# WS53 register map
File version: 0.1.0-experimental
Registers are 32-bit, read-write, no defined reset value unless marked. A register's access mark holds for its fields unless they carry their own. Offsets are from the block's base; [hi:lo] are bit positions; {n}, {i} and the like mark numbered series.

## AUDIO_CMU
Base 0x57008600
0x00 NEW_CFG0 — CMU_NEW_CFG0 partial view; preserve all other bits
  [0] AUDIO_DIVIDER_RESET_N — CMU_DIV_AD_RSTN_SYNC_BIT: SDK sets before I2S gate, clears before disabling gate; shared audio reset ownership required

## GPIO0
Base 0x5700C000
0x00 GPIO_SW_OUT
  [22:0] GPIO_SW_OUT — GPIO data. Output: written value drives I/O; Input: reads external port
0x04 GPIO_SW_OEN
  [22:0] PINS — Direction bitmap: each 0 bit selects output, each 1 bit selects input; not a whole-register mode enum
0x08 GPIO_SW_CTL
  [22:0] GPIO_SW_CTL — Per-pin data source control; SDK supplies bit get/set helpers but does not establish selection encodings
0x0C GPIO_INT_EN
  [22:0] GPIO_INT_EN — Interrupt enable: 0=normal GPIO; 1=interrupt port
0x10 GPIO_INT_MASK
  [22:0] GPIO_INT_MASK — Interrupt mask: 0=not masked; 1=masked
0x14 GPIO_INT_TYPE
  [22:0] PINS — Trigger bitmap: each 0 bit selects level, each 1 bit selects edge
0x18 GPIO_INT_POLARITY
  [22:0] PINS — Polarity bitmap: each 0 bit selects low/falling, each 1 bit high/rising
0x1C GPIO_INT_DEDGE
  [22:0] PINS — Dual-edge bitmap: each 1 bit enables detection on both edges of that input
0x20 GPIO_INT_DEBOUNCE
  [22:0] GPIO_INT_DEBOUNCE — Debounce enable: 0=disabled; 1=enabled
0x24 GPIO_INT_RAW ro
  [22:0] GPIO_INT_RAW — Raw interrupt status (before mask): 0=no interrupt; 1=interrupt
0x28 GPIO_INTR ro
  [22:0] GPIO_INTR — Interrupt status (after mask): 0=no interrupt; 1=interrupt
0x2C GPIO_INT_EOI wo
  [22:0] GPIO_INT_EOI write-1-clears — Edge interrupt clear: 0=no clear; 1=clear interrupt
0x30 GPIO_DATA_SET wo
  [22:0] GPIO_DATA_SET write-1-sets — Write 1 to set corresponding GPIO_SW_OUT bits
0x34 GPIO_DATA_CLR wo
  [22:0] GPIO_DATA_CLR write-1-clears — Write 1 to clear corresponding GPIO_SW_OUT bits

## GPIO2
Base 0x57010000
0x00 GPIO_SW_OUT
  [2:0] GPIO_SW_OUT — GPIO data. Output: written value drives I/O; Input: reads external port
0x04 GPIO_SW_OEN
  [2:0] PINS — Direction bitmap: each 0 bit selects output, each 1 bit selects input; not a whole-register mode enum
0x08 GPIO_SW_CTL
  [2:0] GPIO_SW_CTL — Per-pin data source control; SDK supplies bit get/set helpers but does not establish selection encodings
0x0C GPIO_INT_EN
  [2:0] GPIO_INT_EN — Interrupt enable: 0=normal GPIO; 1=interrupt port
0x10 GPIO_INT_MASK
  [2:0] GPIO_INT_MASK — Interrupt mask: 0=not masked; 1=masked
0x14 GPIO_INT_TYPE
  [2:0] PINS — Trigger bitmap: each 0 bit selects level, each 1 bit selects edge
0x18 GPIO_INT_POLARITY
  [2:0] PINS — Polarity bitmap: each 0 bit selects low/falling, each 1 bit high/rising
0x1C GPIO_INT_DEDGE
  [2:0] PINS — Dual-edge bitmap: each 1 bit enables detection on both edges of that input
0x20 GPIO_INT_DEBOUNCE
  [2:0] GPIO_INT_DEBOUNCE — Debounce enable: 0=disabled; 1=enabled
0x24 GPIO_INT_RAW ro
  [2:0] GPIO_INT_RAW — Raw interrupt status (before mask): 0=no interrupt; 1=interrupt
0x28 GPIO_INTR ro
  [2:0] GPIO_INTR — Interrupt status (after mask): 0=no interrupt; 1=interrupt
0x2C GPIO_INT_EOI wo
  [2:0] GPIO_INT_EOI write-1-clears — Edge interrupt clear: 0=no clear; 1=clear interrupt
0x30 GPIO_DATA_SET wo
  [2:0] GPIO_DATA_SET write-1-sets — Write 1 to set corresponding GPIO_SW_OUT bits
0x34 GPIO_DATA_CLR wo
  [2:0] GPIO_DATA_CLR write-1-clears — Write 1 to clear corresponding GPIO_SW_OUT bits

## EFUSE
Base 0x57024000
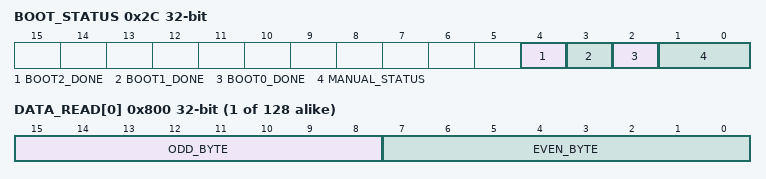
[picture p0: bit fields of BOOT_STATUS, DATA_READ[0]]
0x2C BOOT_STATUS ro
  [4] BOOT2_DONE, [3] BOOT1_DONE, [2] BOOT0_DONE, [1:0] MANUAL_STATUS
0x30 MODE_STATUS ro — Readback of the physical mode register; preserve upper bits when issuing a read-mode command
  [15:0] MODE
0x30 READ_MODE_COMMAND wo (alternate view of MODE_STATUS) — Restricted read-mode view of physical RW control. SDK preserves upper 16 bits; no implicit zeroing or RMW API. Programming mode is not modeled
  [15:0] READ_MODE range 23130..23130
0x34 CLOCK_PERIOD — Shared volatile controller timing; SDK initializes low8 to 0x1f preserving other bits; clock frequency and reset unknown
  [7:0] VALUE
{0x800+4i} DATA_READ[{i}] (i=0..127) ro — Read-only service view of OTP storage: each 32-bit MMIO slot contains two logical bytes; no contiguous byte loads or program writes
  [15:8] ODD_BYTE, [7:0] EVEN_BYTE
